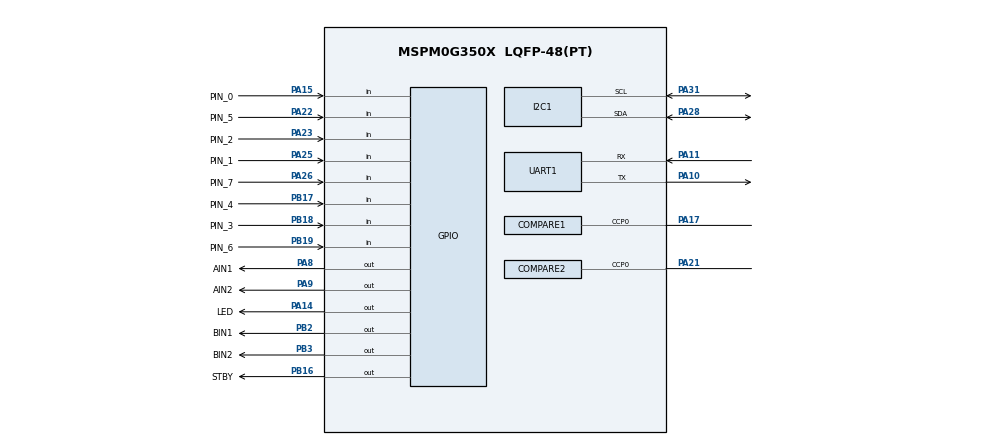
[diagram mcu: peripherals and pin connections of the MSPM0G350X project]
/**
 * @cliArgs --device "MSPM0G350X" --part "Default" --package "LQFP-48(PT)" --product "mspm0_sdk@2.10.00.04"
 * @versions {"tool":"1.27.0+4565"}
 */

/**
 * Import the modules used in this configuration.
 */
const COMPARE  = scripting.addModule("/ti/driverlib/COMPARE", {}, false);
const COMPARE1 = COMPARE.addInstance();
const COMPARE2 = COMPARE.addInstance();
const GPIO     = scripting.addModule("/ti/driverlib/GPIO", {}, false);
const GPIO1    = GPIO.addInstance();
const GPIO2    = GPIO.addInstance();
const GPIO3    = GPIO.addInstance();
const I2C      = scripting.addModule("/ti/driverlib/I2C", {}, false);
const I2C1     = I2C.addInstance();
const PWM      = scripting.addModule("/ti/driverlib/PWM", {}, false);
const PWM1     = PWM.addInstance();
const SYSCTL   = scripting.addModule("/ti/driverlib/SYSCTL");
const TIMER    = scripting.addModule("/ti/driverlib/TIMER", {}, false);
const TIMER1   = TIMER.addInstance();
const UART     = scripting.addModule("/ti/driverlib/UART", {}, false);
const UART1    = UART.addInstance();

/**
 * Write custom configuration values to the imported modules.
 */
const divider9       = system.clockTree["UDIV"];
divider9.divideValue = 2;

const gate7  = system.clockTree["MFCLKGATE"];
gate7.enable = true;

const multiplier2         = system.clockTree["PLL_QDIV"];
multiplier2.multiplyValue = 4;

const mux4       = system.clockTree["EXHFMUX"];
mux4.inputSelect = "EXHFMUX_XTAL";

const mux8       = system.clockTree["HSCLKMUX"];
mux8.inputSelect = "HSCLKMUX_SYSPLL0";

const mux12       = system.clockTree["SYSPLLMUX"];
mux12.inputSelect = "zSYSPLLMUX_HFCLK";

const pinFunction4     = system.clockTree["HFXT"];
pinFunction4.inputFreq = 40;
pinFunction4.enable    = true;

COMPARE1.$name                      = "COMPARE_0";
COMPARE1.timerPeriod                = 65535;
COMPARE1.compareMode                = "EDGE_COUNT_UP";
COMPARE1.peripheral.ccp0Pin.$assign = "PA17";
COMPARE1.ccp0PinConfig.$name        = "ti_driverlib_gpio_GPIOPinGeneric1";

const Board = scripting.addModule("/ti/driverlib/Board", {}, false);

COMPARE2.$name                              = "COMPARE_2";
COMPARE2.timerPeriod                        = 65535;
COMPARE2.compareMode                        = "EDGE_COUNT_UP";
COMPARE2.peripheral.$assign                 = "TIMA0";
COMPARE2.peripheral.ccp0Pin.$assign         = "PA21";
COMPARE2.ccp0PinConfig.hideOutputInversion  = scripting.forceWrite(false);
COMPARE2.ccp0PinConfig.onlyInternalResistor = scripting.forceWrite(false);
COMPARE2.ccp0PinConfig.passedPeripheralType = scripting.forceWrite("Digital");
COMPARE2.ccp0PinConfig.$name                = "ti_driverlib_gpio_GPIOPinGeneric4";

GPIO1.$name                         = "DC_Motor";
GPIO1.associatedPins.create(5);
GPIO1.associatedPins[0].$name       = "AIN1";
GPIO1.associatedPins[0].pin.$assign = "PA8";
GPIO1.associatedPins[1].$name       = "AIN2";
GPIO1.associatedPins[1].pin.$assign = "PA9";
GPIO1.associatedPins[2].$name       = "STBY";
GPIO1.associatedPins[2].pin.$assign = "PB16";
GPIO1.associatedPins[3].$name       = "BIN1";
GPIO1.associatedPins[3].pin.$assign = "PB2";
GPIO1.associatedPins[4].$name       = "BIN2";
GPIO1.associatedPins[4].pin.$assign = "PB3";

GPIO2.$name                          = "ShowStatus";
GPIO2.associatedPins[0].$name        = "LED";
GPIO2.associatedPins[0].assignedPort = "PORTA";
GPIO2.associatedPins[0].pin.$assign  = "PA14";

GPIO3.$name                         = "GPIO_SENSOR";
GPIO3.associatedPins.create(8);
GPIO3.associatedPins[0].$name       = "PIN_0";
GPIO3.associatedPins[0].direction   = "INPUT";
GPIO3.associatedPins[0].pin.$assign = "PA15";
GPIO3.associatedPins[1].$name       = "PIN_1";
GPIO3.associatedPins[1].direction   = "INPUT";
GPIO3.associatedPins[1].pin.$assign = "PA25";
GPIO3.associatedPins[2].$name       = "PIN_2";
GPIO3.associatedPins[2].direction   = "INPUT";
GPIO3.associatedPins[2].pin.$assign = "PA23";
GPIO3.associatedPins[3].$name       = "PIN_3";
GPIO3.associatedPins[3].direction   = "INPUT";
GPIO3.associatedPins[3].pin.$assign = "PB18";
GPIO3.associatedPins[4].$name       = "PIN_4";
GPIO3.associatedPins[4].direction   = "INPUT";
GPIO3.associatedPins[4].pin.$assign = "PB17";
GPIO3.associatedPins[5].$name       = "PIN_5";
GPIO3.associatedPins[5].direction   = "INPUT";
GPIO3.associatedPins[5].pin.$assign = "PA22";
GPIO3.associatedPins[6].$name       = "PIN_6";
GPIO3.associatedPins[6].direction   = "INPUT";
GPIO3.associatedPins[6].pin.$assign = "PB19";
GPIO3.associatedPins[7].$name       = "PIN_7";
GPIO3.associatedPins[7].direction   = "INPUT";
GPIO3.associatedPins[7].pin.$assign = "PA26";

I2C1.basicEnableController             = true;
I2C1.basicControllerStandardBusSpeed   = "Fast";
I2C1.intController                     = ["NACK","RXFIFO_TRIGGER","RX_DONE","STOP","TXFIFO_TRIGGER","TX_DONE"];
I2C1.$name                             = "I2C_GYRO";
I2C1.peripheral.$assign                = "I2C0";
I2C1.peripheral.sdaPin.$assign         = "PA28";
I2C1.peripheral.sclPin.$assign         = "PA31";
I2C1.sdaPinConfig.hideOutputInversion  = scripting.forceWrite(false);
I2C1.sdaPinConfig.onlyInternalResistor = scripting.forceWrite(false);
I2C1.sdaPinConfig.passedPeripheralType = scripting.forceWrite("Digital");
I2C1.sdaPinConfig.$name                = "ti_driverlib_gpio_GPIOPinGeneric6";
I2C1.sclPinConfig.hideOutputInversion  = scripting.forceWrite(false);
I2C1.sclPinConfig.onlyInternalResistor = scripting.forceWrite(false);
I2C1.sclPinConfig.passedPeripheralType = scripting.forceWrite("Digital");
I2C1.sclPinConfig.$name                = "ti_driverlib_gpio_GPIOPinGeneric7";

PWM1.$name                              = "PWMA";
PWM1.timerStartTimer                    = true;
PWM1.timerCount                         = 4000;
PWM1.pwmMode                            = "EDGE_ALIGN_UP";
PWM1.peripheral.$assignAllowConflicts   = "TIMG0";
PWM1.PWM_CHANNEL_0.$name                = "ti_driverlib_pwm_PWMTimerCC0";
PWM1.PWM_CHANNEL_1.$name                = "ti_driverlib_pwm_PWMTimerCC1";
PWM1.ccp0PinConfig.direction            = scripting.forceWrite("OUTPUT");
PWM1.ccp0PinConfig.hideOutputInversion  = scripting.forceWrite(false);
PWM1.ccp0PinConfig.onlyInternalResistor = scripting.forceWrite(false);
PWM1.ccp0PinConfig.passedPeripheralType = scripting.forceWrite("Digital");
PWM1.ccp0PinConfig.$name                = "ti_driverlib_gpio_GPIOPinGeneric0";
PWM1.ccp1PinConfig.$name                = "ti_driverlib_gpio_GPIOPinGeneric5";
PWM1.ccp1PinConfig.direction            = scripting.forceWrite("OUTPUT");
PWM1.ccp1PinConfig.hideOutputInversion  = scripting.forceWrite(false);
PWM1.ccp1PinConfig.onlyInternalResistor = scripting.forceWrite(false);
PWM1.ccp1PinConfig.passedPeripheralType = scripting.forceWrite("Digital");

SYSCTL.forceDefaultClkConfig = true;
SYSCTL.clockTreeEn           = true;

TIMER1.$name              = "TIMER_0";
TIMER1.timerPeriod        = "10 ms";
TIMER1.interrupts         = ["ZERO"];
TIMER1.timerMode          = "PERIODIC";
TIMER1.peripheral.$assign = "TIMG12";

UART1.$name                    = "UART_0";
UART1.targetBaudRate           = 115200;
UART1.interruptPriority        = "3";
UART1.enabledInterrupts        = ["RX","TX"];
UART1.peripheral.rxPin.$assign = "PA11";
UART1.peripheral.txPin.$assign = "PA10";
UART1.txPinConfig.$name        = "ti_driverlib_gpio_GPIOPinGeneric2";
UART1.rxPinConfig.$name        = "ti_driverlib_gpio_GPIOPinGeneric3";

const ProjectConfig              = scripting.addModule("/ti/project_config/ProjectConfig", {}, false);
ProjectConfig.migrationCondition = true;

/**
 * Pinmux solution for unlocked pins/peripherals. This ensures that minor changes to the automatic solver in a future
 * version of the tool will not impact the pinmux you originally saw.  These lines can be completely deleted in order to
 * re-solve from scratch.
 */
pinFunction4.peripheral.$suggestSolution           = "SYSCTL";
pinFunction4.peripheral.hfxInPin.$suggestSolution  = "PA5";
pinFunction4.peripheral.hfxOutPin.$suggestSolution = "PA6";
COMPARE1.peripheral.$suggestSolution               = "TIMA1";
Board.peripheral.$suggestSolution                  = "DEBUGSS";
Board.peripheral.swclkPin.$suggestSolution         = "PA20";
Board.peripheral.swdioPin.$suggestSolution         = "PA19";
PWM1.peripheral.ccp0Pin.$suggestSolution           = "PA12";
PWM1.peripheral.ccp1Pin.$suggestSolution           = "PA13";
UART1.peripheral.$suggestSolution                  = "UART0";
